# LPC18xx register map
File version: 18
Registers are 32-bit, read-write, reset 0x0 unless marked. A register's access mark holds for its fields unless they carry their own. Offsets are from the block's base; [hi:lo] are bit positions; {n}, {i} and the like mark numbered series.

## SCT — Product name title=UM10430 Chapter title=LPC18xx State Configurable Timer (SCT) Modification date=1/18/2011 Major revision=0 Minor revision=7
Base 0x40000000
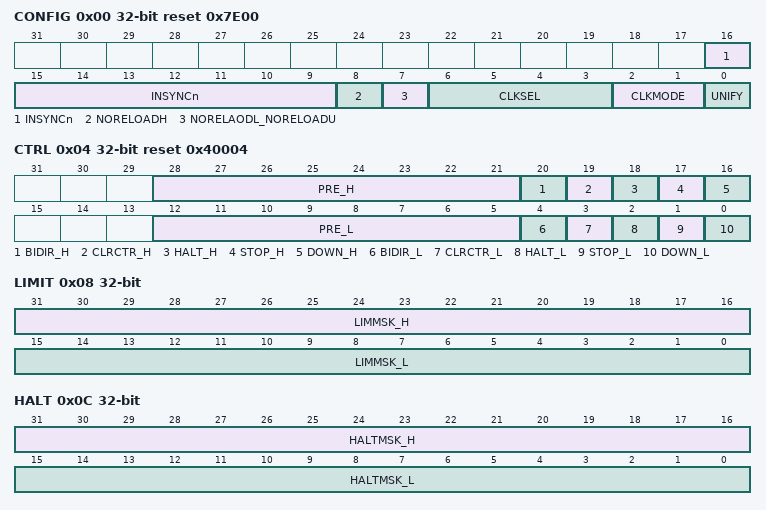
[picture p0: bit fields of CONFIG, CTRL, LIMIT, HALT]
0x00 CONFIG reset 0x7E00 — SCT configuration register
  [16:9] INSYNCn — Synchronization for input n (bit 9 = input 0, bit 10 = input 1,..., bit 16 = input 7). A 1 in one of these bits subjects the corresponding input to synchronization to the SCT clock, before it is used to create an event. If an input is synchronous to the SCT clock, keep its bit 0 for faster response. When the CKMODE field is 1x, the bit in this field, corresponding to the input selected by the CKSEL field, is not used.
  [8] NORELOADH — A 1 in this bit prevents the higher match registers from being reloaded from their respective reload registers. Software can write to set or clear this bit at any time. This bit is not used when the UNIFY bit is set.
  [7] NORELAODL_NORELOADU — A 1 in this bit prevents the lower match registers from being reloaded from their respective reload registers. Software can write to set or clear this bit at any time. This bit applies to both the higher and lower registers when the UNIFY bit is set.
  [6:3] CLKSEL — SCT clock select
    0=INP0_RISING (Rising edges on input 0.); 1=INP0_FALLING (Falling edges on input 0.); 2=INP1_RISING (Rising edges on input 1.); 3=INP1_FALLING (Falling edges on input 1.); 4=INP2_RISING (Rising edges on input 2.); 5=INP2_FALLING (Falling edges on input 2.); 6=INP3_RISING (Rising edges on input 3.); 7=INP3_FALLING (Falling edges on input 3.); 8=INP4_RISING (Rising edges on input 4.); 9=INP4_FALLING (Falling edges on input 4.); 10=INP5_RISING (Rising edges on input 5.); 11=INP5_FALLING (Falling edges on input 5.); 12=INP6_RISING (Rising edges on input 6.); 13=INP6_FALLING (Falling edges on input 6.); 14=INP7_RISING (Rising edges on input 7.); 15=INP7_FALLING (Falling edges on input 7.)
  [2:1] CLKMODE — SCT clock mode
    0=BUS_CLOCK (The SCT and prescaler(s) are clocked by the bus clock.); 1=HIGH_PERFORMANCE (The SCT clock is the bus clock, but the prescaler(s) is (are) enabledto count only when sampling of the input selected by the CKSEfield finds the selected edge. The minimum pulse width on theclock input is 1 bus clock period. This is the highperformance sampled-clock mode.); 2=LOW_POWER (The SCT and prescaler(s) are clocked by the input selected by CKSEL, synchronized to the bus clock and possibly inverted. The minimum pulse width on the clock input is 1 bus clock period. This is the low-power sampled-clock mode.); 3=INPUT_EDGE (The SCT and prescaler(s) are clocked by the input edge selected by the CKSEL field. In this mode the following is true: Most of the SCT is clocked by the (selected polarity of the) input. Outputs are switched synchronously to the input clock. The input clock rate must be at least half the bus clock rate and can be faster than the bus clock.)
  [0] UNIFY — SCT operation
    0=16_BIT_COUNTERS (The SCT operates as two 16-bit counters named L and H.); 1=32_BIT_UNIFIED (The SCT operates as a unified 32-bit counter.)
0x04 CTRL reset 0x40004 — SCT control register
  [28:21] PRE_H — Specifies the factor by which the SCT clock is prescaled to produce the H counter clock. The counter clock will be clocked at the rate of the SCT clock divided by PRELH+1. Clear the counter (by writing a 1 to the CLRCTR bit) whenever changing the PRE value.
  [20] BIDIR_H — Direction select
    0=CLEAR (The H counter counts up to its limit condition, then is cleared to zero.); 1=COUNTDOWN (The H counter counts up to its limit, then counts down to 0.)
  [19] CLRCTR_H — Writing a 1 to this bit clears the H counter. This bit always reads as 0.
  [18] HALT_H — When this bit is 1, the H counter does not run and no events can occur. This bit is set by reset. Once set, this bit can only be cleared by software to restore counter operation.
  [17] STOP_H — When this bit is 1 and HALT is 0, the H counter does not run but I/O events related to the counter can occur. If such an event matches the mask in the Start register, this bit is cleared and counting resumes.
  [16] DOWN_H — This bit is 1 when the H counter is counting down. It is set by hardware when the counter's limit is reached and BIDIR is 1. It is cleared by hardware when the counter reaches 0.
  [12:5] PRE_L — Specifies the factor by which the SCT clock is prescaled to produce the L or unified counter clock. The counter clock will be clocked at the rate of the SCT clock divided by PRE_L+1. Clear the counter (by writing a 1 to the CLRCTR bit) whenever changing the PRE value.
  [4] BIDIR_L — L or unified counter direction select
    0=CLEAR (The counter counts up to its limit condition, then is cleared to zero.); 1=COUNTDOWN (The counter counts up to its limit, then counts down to 0.)
  [3] CLRCTR_L — Writing a 1 to this bit clears the L or unified counter. This bit always reads as 0.
  [2] HALT_L — When this bit is 1, the L or unified counter does not run and no events can occur. This bit is set by reset. Once set, this bit can only be cleared by software to restore counter operation.
  [1] STOP_L — When this bit is 1 and HALT is 0, the L or unified counter does not run but I/O events related to the counter can occur. If such an event matches the mask in the Start register, this bit is cleared and counting resumes.
  [0] DOWN_L — This bit is 1 when the L or unified counter is counting down. It is set by hardware when the counter's limit is reached and BIDIR is 1. It is cleared by hardware when the counter reaches 0.
0x08 LIMIT — SCT limit register
  [31:16] LIMMSK_H — If bit n is one, event n is used as a counter limit for the H counter (event 0 = bit 16, event 1 = bit 17, event 15 = bit 31).
  [15:0] LIMMSK_L — If bit n is one, event n is used as a counter limit for the L or unified counter (event 0 = bit 0, event 1 = bit 1, event 15 = bit 15).
0x0C HALT — SCT halt condition register
  [31:16] HALTMSK_H — If bit n is one, event n sets the HALT_H bit in the SCTCTRL register (event 0 = bit 16, event 1 = bit 17, event 15 = bit 31).
  [15:0] HALTMSK_L — If bit n is one, event n sets the HALT_L bit in the SCTCTRL register (event 0 = bit 0, event 1 = bit 1, event 15 = bit 15).
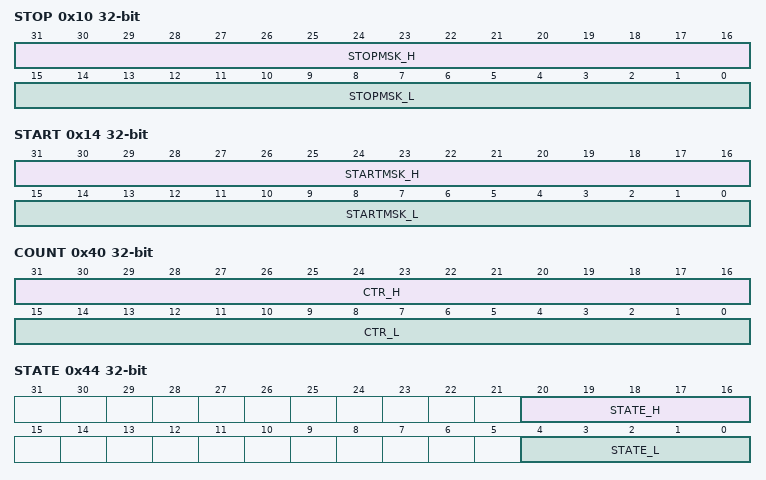
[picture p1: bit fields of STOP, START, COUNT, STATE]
0x10 STOP — SCT stop condition register
  [31:16] STOPMSK_H — If bit n is one, event n sets the STOP_H bit in the SCTCTRL register (event 0 = bit 16, event 1 = bit 17, event 15 = bit 31).
  [15:0] STOPMSK_L — If bit n is one, event n sets the STOP_L bit in the SCTCTRL register (event 0 = bit 0, event 1 = bit 1, event 15 = bit 15).
0x14 START — SCT start condition register
  [31:16] STARTMSK_H — If bit n is one, event n clears the STOP_H bit in the SCTCTRL register (event 0 = bit 16, event 1 = bit 17, event 15 = bit 31).
  [15:0] STARTMSK_L — If bit n is one, event n clears the STOP_L bit in the SCTCTRL register (event 0 = bit 0, event 1 = bit 1, event 15 = bit 15).
0x40 COUNT — SCT counter register
  [31:16] CTR_H — When UNIFY = 0, read or write the 16-bit H counter value. When UNIFY = 1, read or write the upper 16 bits of the 32-bit unified counter.
  [15:0] CTR_L — When UNIFY = 0, read or write the 16-bit L counter value. When UNIFY = 1, read or write the lower 16 bits of the 32-bit unified counter.
0x44 STATE — SCT state register
  [20:16] STATE_H — State variable.
  [4:0] STATE_L — State variable.
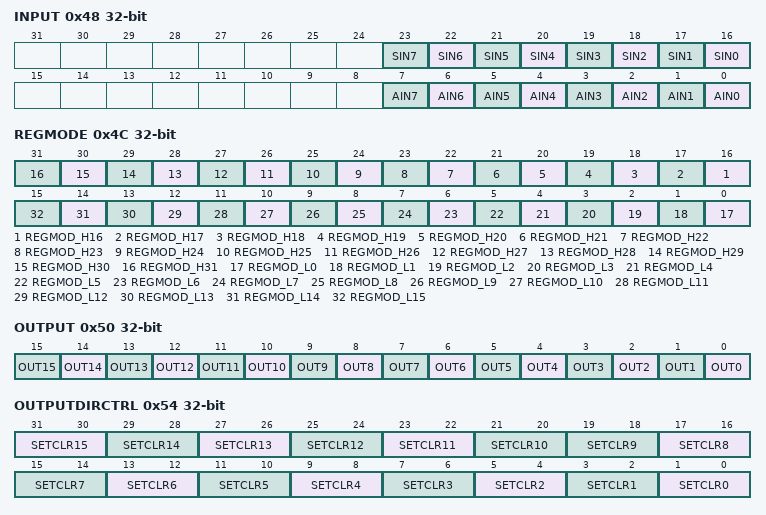
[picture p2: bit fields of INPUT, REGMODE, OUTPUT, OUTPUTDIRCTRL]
0x48 INPUT ro — SCT input register
  [n+16] SIN{n} (n=0..7) — Input {n} state synchronized to the SCT clock.
  [n] AIN{n} (n=0..7) — Real-time status of input {n}.
0x4C REGMODE — SCT match/capture registers mode register
  [n] REGMOD_H{n} (n=16..31) — Each bit controls one pair of match/capture registers (register 0 = bit 16, register 1 = bit 17,..., register 15 = bit 31). 0 = registers operate as match registers. 1 = registers operate as capture registers.
  [n] REGMOD_L{n} (n=0..15) — Each bit controls one pair of match/capture registers (register 0 = bit 0, register 1 = bit 1,..., register 15 = bit 15). 0 = registers operate as match registers. 1 = registers operate as capture registers.
0x50 OUTPUT — SCT output register
  [n] OUT{n} (n=0..15) — Writing a 1 to bit n makes the corresponding output HIGH. 0 makes the corresponding output LOW (output 0 = bit 0, output 1 = bit 1,..., output 15 = bit 15).
0x54 OUTPUTDIRCTRL — SCT output counter direction control register
  [all] fields
    0=INDEPENDENT (Set and clear do not depend on any counter.); 1=REVERSE_L (Set and clear are reversed when counter L or the unified counter is counting down.); 2=REVERSE_H (Set and clear are reversed when counter H is counting down. Do not use if UNIFY = 1.)
  [2n+1:2n] SETCLR{n} (n=11..15) — Set/clear operation on output {n}. Value 0x3 is reserved. Do not program this value.
  [21:20] SETCLR10 — Set/clear operation on output 5. Value 0x3 is reserved. Do not program this value.
  [2n+1:2n] SETCLR{n} (n=0..9) — Set/clear operation on output {n}. Value 0x3 is reserved. Do not program this value.
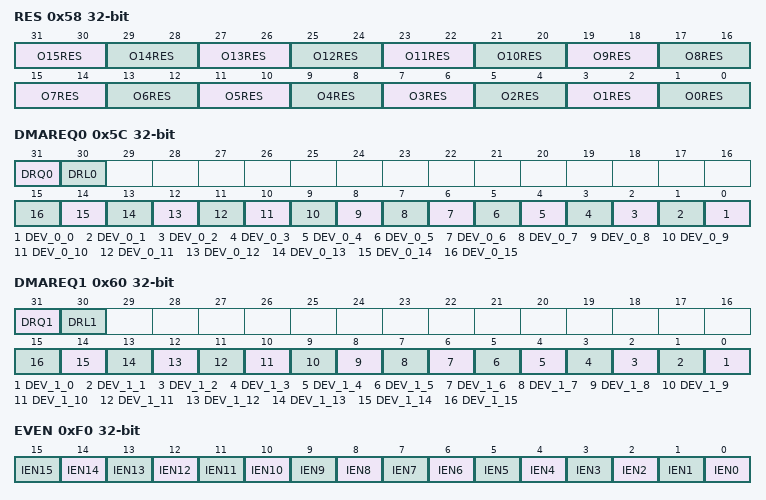
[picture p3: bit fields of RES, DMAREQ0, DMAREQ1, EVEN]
0x58 RES — SCT conflict resolution register
  [2n+1:2n] O{n}RES (n=3..15) — Effect of simultaneous set and clear on output {n}.
    0=NO_CHANGE_; 1=SET_OUTPUT_(OR_CLEAR (Set output (or clear based on the SETCLR{n} field).); 2=CLEAR_OUTPUT_(OR_SET (Clear output (or set based on the SETCLR{n} field).); 3=TOGGLE_OUTPUT_
  [5:4] O2RES — Effect of simultaneous set and clear on output 2.
    0=NO_CHANGE_; 1=SET_OUTPUT_(OR_CLEAR (Set output (or clear based on the SETCLR2 field).); 2=CLEAR_OUTPUT_N_(OR_S (Clear output n (or set based on the SETCLR2 field).); 3=TOGGLE_OUTPUT_
  [3:2] O1RES — Effect of simultaneous set and clear on output 1.
    0=NO_CHANGE_; 1=SET_OUTPUT_(OR_CLEAR (Set output (or clear based on the SETCLR1 field).); 2=CLEAR_OUTPUT_(OR_SET (Clear output (or set based on the SETCLR1 field).); 3=TOGGLE_OUTPUT_
  [1:0] O0RES — Effect of simultaneous set and clear on output 0.
    0=NO_CHANGE_; 1=SET_OUTPUT_(OR_CLEAR (Set output (or clear based on the SETCLR0 field).); 2=CLEAR_OUTPUT_(OR_SET (Clear output (or set based on the SETCLR0 field).); 3=TOGGLE_OUTPUT_
0x5C DMAREQ0 — SCT DMA request 0 register
  [31] DRQ0 — This read-only bit indicates the state of DMA Request 0
  [30] DRL0 — A 1 in this bit makes the SCT set DMA request 0 when it loads the Match_L/Unified registers from the Reload_L/Unified registers.
  [n] DEV_0_{n} (n=0..15) — If bit n is one, event n sets DMA request 0 (event 0 = bit 0, event 1 = bit 1,..., event 15 = bit 15).
0x60 DMAREQ1 — SCT DMA request 1 register
  [31] DRQ1 — This read-only bit indicates the state of DMA Request 1.
  [30] DRL1 — A 1 in this bit makes the SCT set DMA request 1 when it loads the Match L/Unified registers from the Reload L/Unified registers.
  [n] DEV_1_{n} (n=0..15) — If bit n is one, event n sets DMA request 1 (event 0 = bit 0, event 1 = bit 1,..., event 15 = bit 15).
0xF0 EVEN — SCT event enable register
  [n] IEN{n} (n=0..15) — The SCT requests interrupt when bit n of this register and the event flag register are both one (event 0 = bit 0, event 1 = bit 1,..., event 15 = bit 15).
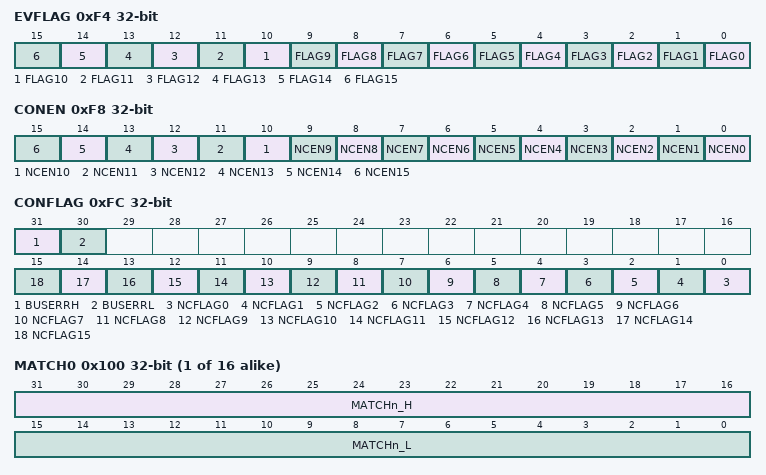
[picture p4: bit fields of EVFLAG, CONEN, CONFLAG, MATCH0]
0xF4 EVFLAG — SCT event flag register
  [n] FLAG{n} (n=0..15) — Bit n is one if event n has occurred since reset or a 1 was last written to this bit (event 0 = bit 0, event 1 = bit 1,..., event 15 = bit 15).
0xF8 CONEN — SCT conflict enable register
  [n] NCEN{n} (n=0..15) — The SCT requests interrupt when bit n of this register and the SCT conflict flag register are both one (output 0 = bit 0, output 1 = bit 1,..., output 15 = bit 15).
0xFC CONFLAG — SCT conflict flag register
  [31] BUSERRH — The most recent bus error from this SCT involved writing CTR H, STATE H, MATCH H, or the Output register when the H counter was not halted.
  [30] BUSERRL — The most recent bus error from this SCT involved writing CTR L/Unified, STATE L/Unified, MATCH L/Unified, or the Output register when the L/U counter was not halted. Note that a word write to certain L and H registers can be half successful and half unsuccessful.
  [n] NCFLAG{n} (n=0..15) — Bit n is one if a no-change conflict event occurred on output n since reset or a 1 was last written to this bit (output 0 = bit 0, output 1 = bit 1,..., output 15 = bit 15).
{0x100+4i} MATCH{i} (i=0..15) — SCT match value register of match channel n; REGMODn = 0
  [31:16] MATCHn_H — When UNIFY = 0, read or write the 16-bit value to be compared to the H counter. When UNIFY = 1, read or write the upper 16 bits of the 32-bit value to be compared to the unified counter.
  [15:0] MATCHn_L — When UNIFY = 0, read or write the 16-bit value to be compared to the L counter. When UNIFY = 1, read or write the lower 16 bits of the 32-bit value to be compared to the unified counter.
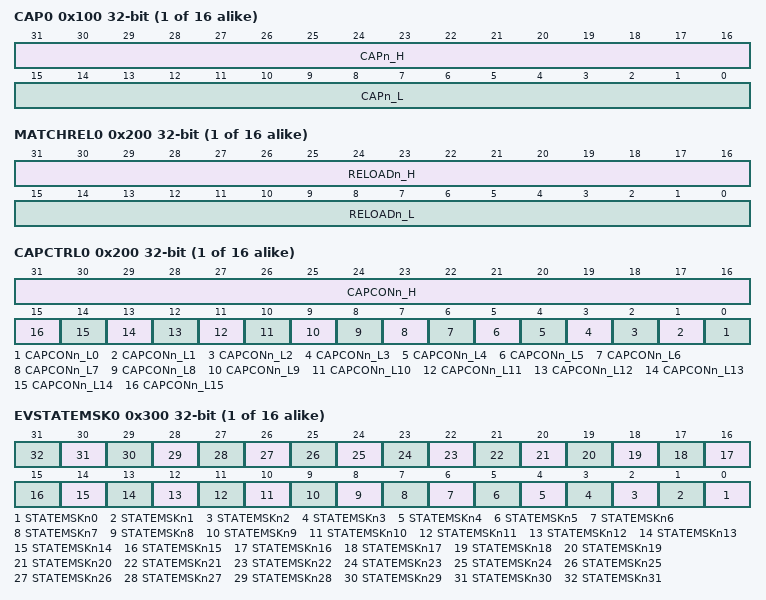
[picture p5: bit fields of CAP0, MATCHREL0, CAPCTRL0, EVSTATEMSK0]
{0x100+4i} CAP{i} (i=0..15) ro (alternate view of MATCH{i}) — SCT capture register of capture channel n; REGMODn = 1
  [31:16] CAPn_H — When UNIFY = 0, read the 16-bit counter value at which this register was last captured. When UNIFY = 1, read the upper 16 bits of the 32-bit value at which this register was last captured.
  [15:0] CAPn_L — When UNIFY = 0, read the 16-bit counter value at which this register was last captured. When UNIFY = 1, read the lower 16 bits of the 32-bit value at which this register was last captured.
{0x200+4i} MATCHREL{i} (i=0..15) — SCT match reload value register ; REGMODn = 0
  [31:16] RELOADn_H — When UNIFY = 0, read or write the 16-bit to be loaded into the SCTMATCHn_H register. When UNIFY = 1, read or write the upper 16 bits of the 32-bit value to be loaded into the SCTMATCHn register.
  [15:0] RELOADn_L — When UNIFY = 0, read or write the 16-bit value to be loaded into the SCTMATCHn_L register. When UNIFY = 1, read or write the lower 16 bits of the 32-bit value to be loaded into the SCTMATCHn register.
{0x200+4i} CAPCTRL{i} (i=0..15) (alternate view of MATCHREL{i}) — SCT capture control register ; REGMODn = 1
  [31:16] CAPCONn_H — If bit m is one, event m causes the SCTCAPn_H (UNIFY = 0) register to be loaded (event 0 = bit 16, event 1 = bit 17,..., event 15 = bit 31).
  [n] CAPCONn_L{n} (n=0..15) — If bit m is one, event m causes the SCTCAPn_L (UNIFY = 0) or the SCTCAPn (UNIFY = 1) register to be loaded (event 0 = bit 0, event 1 = bit 1,..., event 15 = bit 15).
{0x300+8i} EVSTATEMSK{i} (i=0..15) — SCT event state register
  [n] STATEMSKn{n} (n=0..31) — If bit m is one, event n (n= 0 to 15) happens in state m of the counter selected by the HEVENT bit (m = state number; state 0 = bit 0, state 1= bit 1,..., state 31 = bit 31).
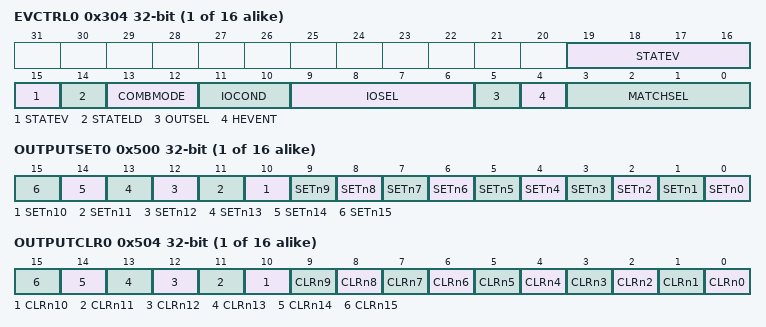
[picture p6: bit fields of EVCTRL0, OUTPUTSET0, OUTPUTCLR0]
{0x304+8i} EVCTRL{i} (i=0..15) — SCT event control register
  [19:15] STATEV — This value is loaded into or added to the state selected by HEVENT, depending on STATELD, when this event is the highest-numbered event occurring for that state. If STATELD and STATEV are both zero, there is no change to the STATE value.
  [14] STATELD — This bit controls how the STATEV value modifies the state selected by HEVENT when this event is the highest-numbered event occurring for that state.
    0=STATEV_VALUE_IS_ADDE (STATEV value is added into STATE (the carry-out is ignored).); 1=STATEV_VALUE_IS_LOAD (STATEV value is loaded into STATE.)
  [13:12] COMBMODE — Selects how the specified match and I/O condition are used and combined.
    0=OR_THE_EVENT_OCCURS (OR. The event occurs when either the specified match or I/O condition occurs.); 1=MATCH_USES_THE_SPEC (MATCH. Uses the specified match only.); 2=IO_USES_THE_SPECIFI (IO. Uses the specified I/O condition only.); 3=AND_THE_EVENT_OCCUR (AND. The event occurs when the specified match and I/O condition occur simultaneously.)
  [11:10] IOCOND — Selects the I/O condition for event n. (Note that the detection of edges on outputs will lag the conditions that switch the outputs by one SCT clock). An input must have a minimum pulse width of at least one SCT clock period in order to guarantee proper edge/state detection.
    0=LOW; 1=RISE; 2=FALL; 3=HIGH
  [9:6] IOSEL — Selects the input or output signal associated with this event (if any). If CKMODE is 1x, the clock input is an implicit ingredient of every event, and should not be selected in this register.
  [5] OUTSEL — Input/output select
    0=SELECTS_THE_OUTPUT_S (Selects the output selected by IOSEL.); 1=SELECTS_THE_INPUT_SE (Selects the input selected by IOSEL.)
  [4] HEVENT — Select L/H counter. Do not set this bit if UNIFY = 1.
    0=SELECTS_THE_L_STATE_ (Selects the L state and the L match register selected by MATCHSEL.); 1=SELECTS_THE_H_STATE_ (Selects the H state and the H match register selected by MATCHSEL.)
  [3:0] MATCHSEL — Selects the Match register associated with this event (if any). A match can occur only when the counter selected by the HEVENT bit is running.
{0x500+8i} OUTPUTSET{i} (i=0..15) — SCT output set register
  [n] SETn{n} (n=0..15) — A 1 in bit m selects event m to set output n (or clear it if SETCLRn = 0x1 or 0x2) event 0 = bit 0, event 1 = bit 1,..., event 15 = bit 15.
{0x504+8i} OUTPUTCLR{i} (i=0..15) — SCT output clear register
  [n] CLRn{n} (n=0..15) — A 1 in bit m selects event m to clear output n (or set it if SETCLRn = 0x1 or 0x2) event 0 = bit 0, event 1 = bit 1,..., event 15 = bit 15.
